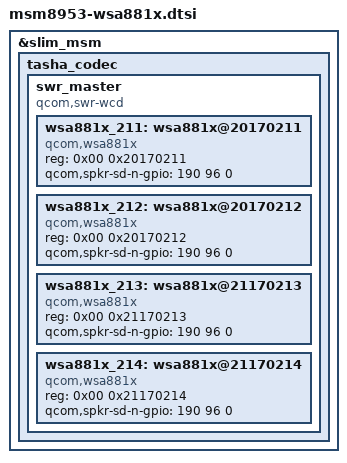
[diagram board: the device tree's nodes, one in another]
/*
 * Copyright (c) 2015-2016, The Linux Foundation. All rights reserved.
 *
 * This program is free software; you can redistribute it and/or modify
 * it under the terms of the GNU General Public License version 2 and
 * only version 2 as published by the Free Software Foundation.
 *
 * This program is distributed in the hope that it will be useful,
 * but WITHOUT ANY WARRANTY; without even the implied warranty of
 * MERCHANTABILITY or FITNESS FOR A PARTICULAR PURPOSE.  See the
 * GNU General Public License for more details.
 */

&slim_msm {
	tasha_codec {
		swr_master {
					compatible = "qcom,swr-wcd";
					#address-cells = <2>;
					#size-cells = <0>;

					wsa881x_211: wsa881x@20170211 {
						compatible = "qcom,wsa881x";
						reg = <0x00 0x20170211>;
						qcom,spkr-sd-n-gpio = <190 96 0>;
						linux,phandle = <0x179>;
						phandle = <0x179>;
					};

					wsa881x_212: wsa881x@20170212 {
						compatible = "qcom,wsa881x";
						reg = <0x00 0x20170212>;
						qcom,spkr-sd-n-gpio = <190 96 0>;
						linux,phandle = <0x17a>;
						phandle = <0x17a>;
					};

					wsa881x_213: wsa881x@21170213 {
						compatible = "qcom,wsa881x";
						reg = <0x00 0x21170213>;
						qcom,spkr-sd-n-gpio = <190 96 0>;
						linux,phandle = <0x17b>;
						phandle = <0x17b>;
					};

					wsa881x_214: wsa881x@21170214 {
						compatible = "qcom,wsa881x";
						reg = <0x00 0x21170214>;
						qcom,spkr-sd-n-gpio = <190 96 0>;
						linux,phandle = <0x17c>;
						phandle = <0x17c>;
					};
				};
	};
};
